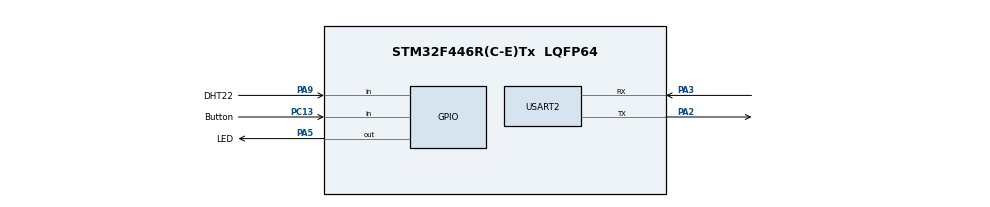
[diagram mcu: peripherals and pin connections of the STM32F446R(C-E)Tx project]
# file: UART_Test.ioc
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Mcu.Family=STM32F4
RCC.CortexFreq_Value=16000000
PA9.GPIO_Label=DHT22
PC13.Signal=GPIO_Input
PC13.GPIO_Label=Button
ProjectManager.StackSize=0x400
PA3.Mode=Asynchronous
ProjectManager.TargetToolchain=STM32CubeIDE
PA9.Signal=GPIO_Input
RCC.USBFreq_Value=96000000
PA5.Signal=GPIO_Output
board=custom
RCC.VCOOutputFreq_Value=192000000
Mcu.Name=STM32F446R(C-E)Tx
PA2.Signal=USART2_TX
Mcu.Package=LQFP64
PA5.GPIO_Label=LED
USART2.VirtualMode=VM_ASYNC
ProjectManager.HeapSize=0x200
NVIC.PriorityGroup=NVIC_PRIORITYGROUP_4
PA2.Mode=Asynchronous
PA3.Signal=USART2_RX

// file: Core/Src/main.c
/* USER CODE BEGIN Header */
/**
  ******************************************************************************
  * @file           : main.c
  * @brief          : Main program body
  ******************************************************************************
  * @attention
  *
  * <h2><center>&copy; Copyright (c) 2021 STMicroelectronics.
  * All rights reserved.</center></h2>
  *
  * This software component is licensed by ST under BSD 3-Clause license,
  * the "License"; You may not use this file except in compliance with the
  * License. You may obtain a copy of the License at:
  *                        opensource.org/licenses/BSD-3-Clause
  *
  ******************************************************************************
  */
/* USER CODE END Header */
#include "main.h"

/* USER CODE BEGIN Includes */
#include "MY_DHT22.h"
/* USER CODE END Includes */

UART_HandleTypeDef huart2;

void SystemClock_Config(void);
static void MX_GPIO_Init(void);
static void MX_USART2_UART_Init(void);

/* USER CODE BEGIN 0 */
float TempC, Humidity;
char uartData[50];

/* USER CODE END 0 */

#define BLINK_TICKS (100)
#define DHT22_Wait (1000)

int main(void)
{

  /* MCU Configuration--------------------------------------------------------*/

  /* Reset of all peripherals, Initializes the Flash interface and the Systick. */
  HAL_Init();

  /* Configure the system clock */
  SystemClock_Config();

  /* Initialize all configured peripherals */
  MX_GPIO_Init();
  MX_USART2_UART_Init();
  /* USER CODE BEGIN 2 */
  DHT22_Init(GPIOA, GPIO_PIN_9);
  /* USER CODE END 2 */

  /* Infinite loop */
  /* USER CODE BEGIN WHILE */

  TempC = 18.90f;
  Humidity = 56.3f;
  while (1)
  {
    /* USER CODE END WHILE */
	  HAL_GPIO_TogglePin(GPIOA, GPIO_PIN_5);
	 /* if(DHT22_GetTemp_Humidity(&TempC, &Humidity) == 1)
		{
			sprintf(uartData, "\r\nTemp (C) =\t %.1f\r\nHumidity (%%) =\t %.1f%%\r\n", TempC, Humidity);
			HAL_UART_Transmit(&huart2, (uint8_t *)uartData, strlen(uartData), 10);
		}
		else
		{
			sprintf(uartData, "\r\nCRC Error!\r\n");
			HAL_UART_Transmit(&huart2, (uint8_t *)uartData, strlen(uartData), 10);
		}*/

	  sprintf(uartData, "\r\nTemp (C) =\t %.2f\r\nHumidity (%%) =\t %.1f%%\r\n", TempC, Humidity);
	  HAL_UART_Transmit(&huart2, (uint8_t *)uartData, strlen(uartData), 10);
      HAL_Delay(DHT22_Wait);
      TempC = TempC + 0.02;
      Humidity = Humidity + 0.1;
  }
}

void SystemClock_Config(void)
{
  RCC_OscInitTypeDef RCC_OscInitStruct = {0};
  RCC_ClkInitTypeDef RCC_ClkInitStruct = {0};

  /** Configure the main internal regulator output voltage
  */
  __HAL_RCC_PWR_CLK_ENABLE();
  __HAL_PWR_VOLTAGESCALING_CONFIG(PWR_REGULATOR_VOLTAGE_SCALE3);
  /** Initializes the RCC Oscillators according to the specified parameters
  * in the RCC_OscInitTypeDef structure.
  */
  RCC_OscInitStruct.OscillatorType = RCC_OSCILLATORTYPE_HSI;
  RCC_OscInitStruct.HSIState = RCC_HSI_ON;
  RCC_OscInitStruct.HSICalibrationValue = RCC_HSICALIBRATION_DEFAULT;
  RCC_OscInitStruct.PLL.PLLState = RCC_PLL_NONE;
  if (HAL_RCC_OscConfig(&RCC_OscInitStruct) != HAL_OK)
  {
    Error_Handler();
  }
  /** Initializes the CPU, AHB and APB buses clocks
  */
  RCC_ClkInitStruct.ClockType = RCC_CLOCKTYPE_HCLK|RCC_CLOCKTYPE_SYSCLK
                              |RCC_CLOCKTYPE_PCLK1|RCC_CLOCKTYPE_PCLK2;
  RCC_ClkInitStruct.SYSCLKSource = RCC_SYSCLKSOURCE_HSI;
  RCC_ClkInitStruct.AHBCLKDivider = RCC_SYSCLK_DIV1;
  RCC_ClkInitStruct.APB1CLKDivider = RCC_HCLK_DIV1;
  RCC_ClkInitStruct.APB2CLKDivider = RCC_HCLK_DIV1;

  if (HAL_RCC_ClockConfig(&RCC_ClkInitStruct, FLASH_LATENCY_0) != HAL_OK)
  {
    Error_Handler();
  }
}

static void MX_USART2_UART_Init(void)
{

  huart2.Instance = USART2;
  huart2.Init.BaudRate = 115200;
  huart2.Init.WordLength = UART_WORDLENGTH_8B;
  huart2.Init.StopBits = UART_STOPBITS_1;
  huart2.Init.Parity = UART_PARITY_NONE;
  huart2.Init.Mode = UART_MODE_TX_RX;
  huart2.Init.HwFlowCtl = UART_HWCONTROL_NONE;
  huart2.Init.OverSampling = UART_OVERSAMPLING_16;
  if (HAL_UART_Init(&huart2) != HAL_OK)
  {
    Error_Handler();
  }

}

static void MX_GPIO_Init(void)
{
  GPIO_InitTypeDef GPIO_InitStruct = {0};

  /* GPIO Ports Clock Enable */
  __HAL_RCC_GPIOC_CLK_ENABLE();
  __HAL_RCC_GPIOA_CLK_ENABLE();

  /*Configure GPIO pin Output Level */
  HAL_GPIO_WritePin(LED_GPIO_Port, LED_Pin, GPIO_PIN_RESET);

  /*Configure GPIO pin : Button_Pin */
  GPIO_InitStruct.Pin = Button_Pin;
  GPIO_InitStruct.Mode = GPIO_MODE_INPUT;
  GPIO_InitStruct.Pull = GPIO_NOPULL;
  HAL_GPIO_Init(Button_GPIO_Port, &GPIO_InitStruct);

  /*Configure GPIO pin : LED_Pin */
  GPIO_InitStruct.Pin = LED_Pin;
  GPIO_InitStruct.Mode = GPIO_MODE_OUTPUT_PP;
  GPIO_InitStruct.Pull = GPIO_NOPULL;
  GPIO_InitStruct.Speed = GPIO_SPEED_FREQ_LOW;
  HAL_GPIO_Init(LED_GPIO_Port, &GPIO_InitStruct);

  /*Configure GPIO pin : DHT22_Pin */
  GPIO_InitStruct.Pin = DHT22_Pin;
  GPIO_InitStruct.Mode = GPIO_MODE_INPUT;
  GPIO_InitStruct.Pull = GPIO_NOPULL;
  HAL_GPIO_Init(DHT22_GPIO_Port, &GPIO_InitStruct);

}

void Error_Handler(void)
{
  __disable_irq();
  while (1)
  {
  }
}

/************************ (C) COPYRIGHT STMicroelectronics *****END OF FILE****/
